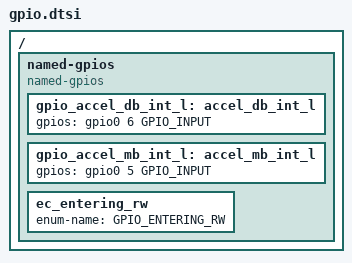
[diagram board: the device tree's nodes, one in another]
/* Copyright 2025 The ChromiumOS Authors
 * Use of this source code is governed by a BSD-style license that can be
 * found in the LICENSE file.
 */
#include <dt-bindings/gpio_defines.h>

/ {
	named-gpios {
		compatible = "named-gpios";

		gpio_accel_db_int_l: accel_db_int_l {
			gpios = <&gpio0 6 GPIO_INPUT>;
		};

		gpio_accel_mb_int_l: accel_mb_int_l {
			gpios = <&gpio0 5 GPIO_INPUT>;
		};

		ec_entering_rw {
			enum-name = "GPIO_ENTERING_RW";
		};
	};
};
